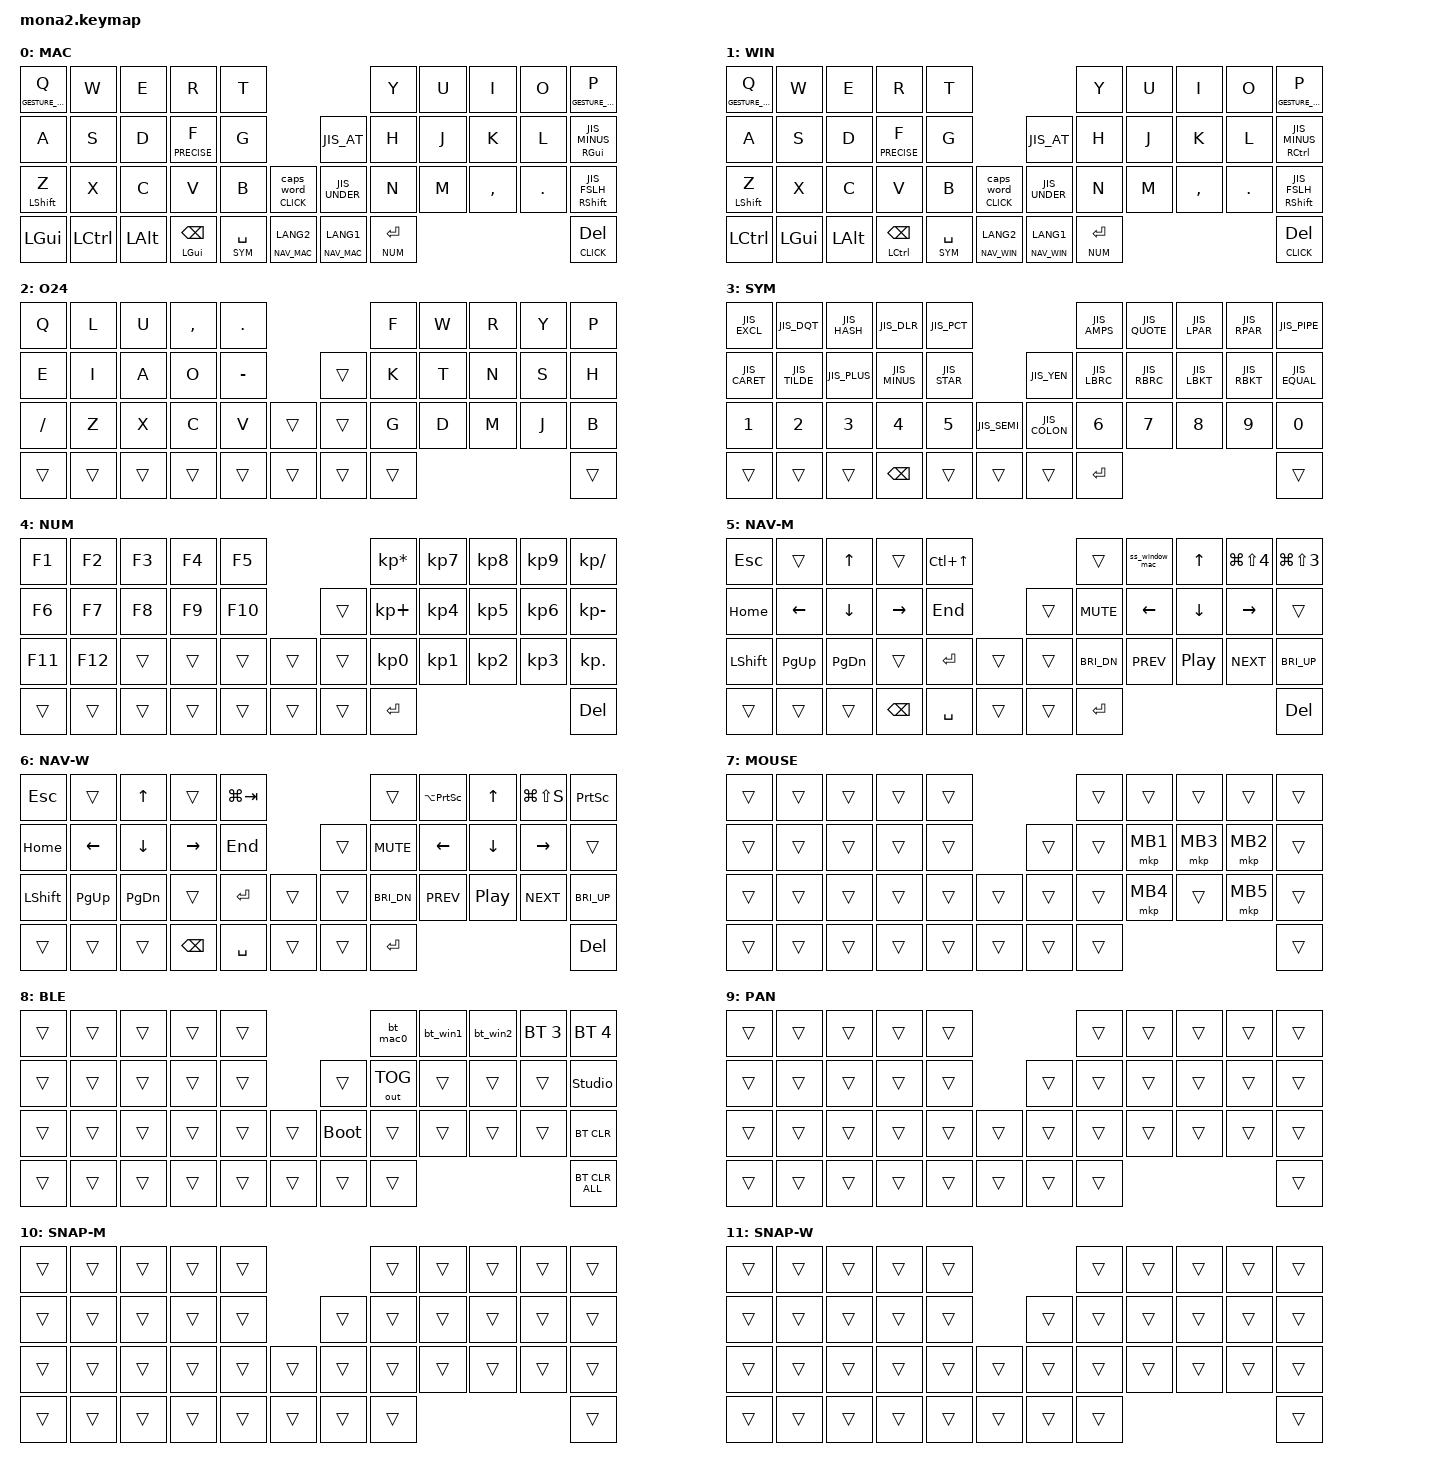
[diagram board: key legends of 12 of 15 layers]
/*
 * moNa2 keymap - JIS運用 / WIN・MAC分離 / DYA Studio対応
 * 設計: docs/keymap-phase1.md
 * レイアウト図: keymap-drawer/mona2_jis.svg
 */

#include <input/processors.dtsi>
#include <input/processors/runtime-input-processor.dtsi>
#include <behaviors/runtime-sensor-rotate.dtsi>
// DYA Studio で作ったマクロを &rmacro <slot> でキーに割り当てられるようにする
#include <behaviors/runtime_macro.dtsi>
#include <dt-bindings/zmk/input_transform.h>
#include <zephyr/dt-bindings/input/input-event-codes.h>
#include "jis.h"
#include <dt-bindings/zmk/mouse-gesture.h>
#include <behaviors.dtsi>
#include <dt-bindings/zmk/bt.h>
#include <dt-bindings/zmk/keys.h>
#include <dt-bindings/zmk/outputs.h>
#include <dt-bindings/zmk/pointing.h>

/* エンコーダ1クリックのスクロール量 ≈ SCRL_VAL × MSC_TICK_MS × (tap-ms 中の tick 数) / 1000。
 * &msc は MSC_TICK_MS ごとにスクロールを出す。tap-ms=20 だと tick は 8/16ms の2回なので
 * 130 × 0.008 × 2 ≈ 2 段。旧設定 (30, 16ms, tap-ms=100) も 0.48 × 6 tick ≈ 2 段で量は同じ。
 * 1クリックでビヘイビアキューが tap-ms だけ止まるので、tap-ms=20 なら毎秒約50クリック
 * (5回転) まで遅れずに追従する。旧 100ms では毎秒10クリックで、一気に回すと追いつきが長かった */
#define ZMK_POINTING_DEFAULT_SCRL_VAL 130
#define MSC_TICK_MS 8

/* mod-tap 誤爆対策 (&mt / mt_bspc):
 * 直前のキー入力からこの時間(ms)以内は hold(修飾キー)が発動せず tap 扱いになる。
 * 0 にすると無効化(従来挙動) */
#define MT_REQUIRE_PRIOR_IDLE_MS 125

/* ---- レイヤー定義 ---- */

#define MAC          0   // ベース(Mac)        — デフォルト
#define WIN          1   // ベース(Windows)
#define O24          2   // 代替アルファ（Q+Pトグル）
#define SYM          3   // 記号
#define NUM          4   // 数字(右手テンキー)
#define NAV_MAC      5   // 矢印/ナビ(Mac)     — P=Cmd+Shift+3
#define NAV_WIN      6   // 矢印/ナビ(Windows) — P=PrtSc
#define MOUSE        7   // マウス(オートマウスレイヤー)
#define BLE          8   // BT/設定
#define GESTURE_PAN  9   // P長押し → 2D自由スクロール(パン)
#define GESTURE_SNAP_MAC 10  // Q長押し(Mac) → ウィンドウスナップ(Rectangle)
#define GESTURE_SNAP_WIN 11  // Q長押し(Win) → ウィンドウスナップ(Win+矢印)
#define CURSOR       12  // (現在未使用)  長押し → トラックボールで矢印キー入力
#define CLICK        13  // 長押し → クリック層（カーソル移動はそのまま、指でクリック）
#define PRECISE      14  // F 長押し(400ms) → 精密モード（カーソル減速 + 右手クリック）

/* エンコーダ用 &msc の出力間隔 (既定 16ms)。短くして1クリック目からすぐスクロールさせる */
&msc {
    trigger-period-ms = <MSC_TICK_MS>;
};

&mt {
    flavor = "balanced";
    quick-tap-ms = <0>;
#if MT_REQUIRE_PRIOR_IDLE_MS > 0
    require-prior-idle-ms = <MT_REQUIRE_PRIOR_IDLE_MS>;
#endif
};

&lt {
    quick-tap-ms = <200>;
    flavor = "balanced";
};

/ {
    /* ---- コンボ (DYA Studio から編集可能) ----
     *
     * 旧 `combos { compatible = "zmk,combos"; }` はコンパイル時固定で DYA Studio
     * から編集できないため、zmk-feature-runtime-combo の「コンパイル時デフォルト」
     * ノードへ移行した。ここに書いた内容はフラッシュ直後から有効で、
     * settings_reset をかけても復活する。
     *
     * 【重要】DYA Studio 側で編集するとそのスロットだけフラッシュ上で上書きされ、
     * 以後 .keymap を書き換えても反映されない。ファーム側の値へ戻すには
     * Web UI の "Reset to Default" か settings_reset.uf2 が必要。
     *
     * スロット総数は CONFIG_ZMK_RUNTIME_COMBO_MAX_COMBOS (=16)。
     * 未使用スロット 8〜15 は DYA Studio から自由に追加できる。
     * timeout の既定は CONFIG_ZMK_RUNTIME_COMBO_DEFAULT_TIMEOUT_MS (=50、旧 zmk,combos と同値)。
     */
    runtime_combo_defaults {
        compatible = "cormoran,runtime-combo-defaults";

        // S+D = Tab
        combo_tab {
            slot = <0>;
            display-name = "Tab";
            bindings = <&kp TAB>;
            key-positions = <11 12>;
            layers = <WIN MAC>;
        };

        // D+F = Shift+Tab
        combo_stab {
            slot = <1>;
            display-name = "Shift+Tab";
            bindings = <&kp LS(TAB)>;
            key-positions = <12 13>;
            layers = <WIN MAC>;
        };

        // 英数+かな = tap:Esc / hold:BLE層 (sayu-hub意識)
        // NOTE: BLE 層は studio_unlock の唯一の入口。Studio でこのスロットを
        //       壊すと Studio に入れなくなるが、settings_reset.uf2 で復旧できる。
        combo_esc_ble {
            slot = <2>;
            display-name = "Esc / BLE";
            bindings = <&lt BLE ESC>;
            key-positions = <38 39>;
            layers = <WIN MAC O24>;  // O24 トグル中も BLE 層へ入れるよう含める
        };

        // J+K = コピー / K+L = ペースト (OS別に修飾を分岐)
        combo_copy_mac {
            slot = <3>;
            display-name = "Copy (Mac)";
            bindings = <&kp LG(C)>;
            key-positions = <17 18>;
            layers = <MAC>;
        };

        combo_copy_win {
            slot = <4>;
            display-name = "Copy (Win)";
            bindings = <&kp LC(C)>;
            key-positions = <17 18>;
            layers = <WIN>;
        };

        combo_paste_mac {
            slot = <5>;
            display-name = "Paste (Mac)";
            bindings = <&kp LG(V)>;
            key-positions = <18 19>;
            layers = <MAC>;
        };

        combo_paste_win {
            slot = <6>;
            display-name = "Paste (Win)";
            bindings = <&kp LC(V)>;
            key-positions = <18 19>;
            layers = <WIN>;
        };

        combo_toO24 {
            slot = <7>;
            display-name = "O24 toggle";
            bindings = <&tog O24>;
            key-positions = <0 9>;
            layers = <MAC WIN O24>;  // 機能層での Q+P 誤爆を防止
        };
    };

    macros {
        // OSをBTプロファイルに紐づけて切替 (BT0=Mac / BT1=Win / BT2=Win)

        bt_mac0: bt_mac0 {
            compatible = "zmk,behavior-macro";
            #binding-cells = <0>;
            bindings = <&to MAC &bt BT_SEL 0>;
            label = "BT_MAC0";
        };

        bt_win1: bt_win1 {
            compatible = "zmk,behavior-macro";
            #binding-cells = <0>;
            bindings = <&to WIN &bt BT_SEL 1>;
            label = "BT_WIN1";
        };

        bt_win2: bt_win2 {
            compatible = "zmk,behavior-macro";
            #binding-cells = <0>;
            bindings = <&to WIN &bt BT_SEL 2>;
            label = "BT_WIN2";
        };

        // Mac: ⌘⇧4 → Space で「ウィンドウ単位」スクショ (2段操作をマクロ化)

        ss_window_mac: ss_window_mac {
            compatible = "zmk,behavior-macro";
            #binding-cells = <0>;
            wait-ms = <50>;
            tap-ms = <30>;
            bindings = <&kp LG(LS(N4)) &kp SPACE>;
            label = "SS_WINDOW_MAC";
        };

        // Win: 対角スナップ (2ストローク: Win+方向 × 2)

        snap_w_tl: snap_w_tl {
            compatible = "zmk,behavior-macro";
            #binding-cells = <0>;
            wait-ms = <50>;
            tap-ms = <30>;
            bindings = <&kp LG(LEFT) &kp LG(UP)>;
            label = "SNAP_W_TL";
        };

        snap_w_tr: snap_w_tr {
            compatible = "zmk,behavior-macro";
            #binding-cells = <0>;
            wait-ms = <50>;
            tap-ms = <30>;
            bindings = <&kp LG(RIGHT) &kp LG(UP)>;
            label = "SNAP_W_TR";
        };

        snap_w_bl: snap_w_bl {
            compatible = "zmk,behavior-macro";
            #binding-cells = <0>;
            wait-ms = <50>;
            tap-ms = <30>;
            bindings = <&kp LG(LEFT) &kp LG(DOWN)>;
            label = "SNAP_W_BL";
        };

        snap_w_br: snap_w_br {
            compatible = "zmk,behavior-macro";
            #binding-cells = <0>;
            wait-ms = <50>;
            tap-ms = <30>;
            bindings = <&kp LG(RIGHT) &kp LG(DOWN)>;
            label = "SNAP_W_BR";
        };
    };

    behaviors {
        // Backspace 専用 mod-tap: タップ→即長押し(quick-tap)で BS をオートリピート

        mt_bspc: mt_bspc {
            compatible = "zmk,behavior-hold-tap";
            #binding-cells = <2>;
            bindings = <&kp>, <&kp>;

            flavor = "balanced";
            tapping-term-ms = <200>;
            quick-tap-ms = <200>;
#if MT_REQUIRE_PRIOR_IDLE_MS > 0
            require-prior-idle-ms = <MT_REQUIRE_PRIOR_IDLE_MS>;
#endif
        };

        // エンコーダ: runtime-sensor-rotate (DYA Studioから動的変更可)

        scroll_up_down: scroll_up_down {
            compatible = "zmk,behavior-runtime-sensor-rotate";
            #sensor-binding-cells = <0>;
            cw-binding = <&msc SCRL_DOWN>;
            ccw-binding = <&msc SCRL_UP>;
            // 1クリックでキューが tap-ms だけ止まる。100ms だと毎秒10クリックしか
            // 捌けず追いつきが長いので 20ms に (量は SCRL_VAL / MSC_TICK_MS 側で合わせてある)
            tap-ms = <20>;
        };

        rsr_vol: rsr_vol {
            compatible = "zmk,behavior-runtime-sensor-rotate";
            #sensor-binding-cells = <0>;
            cw-binding = <&kp C_VOL_DN>;
            ccw-binding = <&kp C_VOL_UP>;
            // 音量キーは押下時間で量が変わらないので、追いつきが速くなるよう短くする
            tap-ms = <20>;
        };

        // クリック層用 hold-tap: タップ=caps_word / 長押し=クリック層(CLICK)
        // caps_word は #binding-cells=0 のため、起動時はタップ側パラメータ(0)を渡すが caps_word は無視する
        clk_caps: clk_caps {
            compatible = "zmk,behavior-hold-tap";
            #binding-cells = <2>;
            flavor = "balanced";
            tapping-term-ms = <200>;
            quick-tap-ms = <200>;
            bindings = <&mo>, <&caps_word>;
        };

        // 精密モード用 hold-tap: タップ=通常の文字 / 長押し(400ms)=精密層(PRECISE)
        //
        // flavor が "tap-preferred" なのが肝。&lt や &mt が使う "balanced" は
        // 「他のキーが押されて離された」時点で hold 判定するため、F をこの方式に
        // すると `fa` `fo` と打っただけで層に落ちる。tap-preferred は
        // 「tapping-term の経過」でしか hold にならないので、
        //   - 通常のタイピングでは原理的に発動しない
        //   - D+F コンボ (timeout 50ms) が先に成立して抜ける
        // という二重の保護になる。「長押しで入る」という要求と手段が一致している。
        //
        // 代償: hold 判定が確定するまで後続キーが遅延する (`fo` の o が少し待たされる)。
        // 実害が出たら hold-trigger-key-positions で右手キー限定にする手がある。
        prec_ht: prec_ht {
            compatible = "zmk,behavior-hold-tap";
            #binding-cells = <2>;
            flavor = "tap-preferred";
            tapping-term-ms = <400>;   // 精密モードに入るまでの長押し時間。250〜500 で調整
            quick-tap-ms = <200>;      // タップ直後の押しっぱなしは文字のオートリピート
#if MT_REQUIRE_PRIOR_IDLE_MS > 0
            require-prior-idle-ms = <MT_REQUIRE_PRIOR_IDLE_MS>;  // 打鍵直後は発動しない
#endif
            bindings = <&mo>, <&kp>;
        };

    };

    keymap {
        compatible = "zmk,keymap";

        mac_layer {
            display-name = "MAC";
            bindings = <
&lt GESTURE_SNAP_MAC Q  &kp W      &kp E     &kp R               &kp T                                                  &kp Y          &kp U  &kp I      &kp O    &lt GESTURE_PAN P
&kp A                   &kp S      &kp D     &prec_ht PRECISE F  &kp G                       &kp JIS_AT             &kp H          &kp J  &kp K      &kp L    &mt RGUI JIS_MINUS
&mt LSHFT Z             &kp X      &kp C     &kp V               &kp B        &clk_caps CLICK 0     &kp JIS_UNDER          &kp N          &kp M  &kp COMMA  &kp DOT  &mt RSHFT JIS_FSLH
&kp LGUI                &kp LCTRL  &kp LALT  &mt_bspc LGUI BSPC  &lt SYM SPACE  &lt NAV_MAC LANG2    &lt NAV_MAC LANG1  &lt NUM ENTER                             &lt CLICK DEL
            >;

            sensor-bindings = <&scroll_up_down>;
        };

        win_layer {
            display-name = "WIN";
            bindings = <
&lt GESTURE_SNAP_WIN Q  &kp W     &kp E     &kp R                &kp T                                                  &kp Y          &kp U  &kp I      &kp O    &lt GESTURE_PAN P
&kp A                  &kp S     &kp D     &prec_ht PRECISE F   &kp G                       &kp JIS_AT             &kp H          &kp J  &kp K      &kp L    &mt RCTRL JIS_MINUS
&mt LSHFT Z            &kp X     &kp C     &kp V                &kp B        &clk_caps CLICK 0     &kp JIS_UNDER          &kp N          &kp M  &kp COMMA  &kp DOT  &mt RSHFT JIS_FSLH
&kp LCTRL              &kp LGUI  &kp LALT  &mt_bspc LCTRL BSPC  &lt SYM SPACE  &lt NAV_WIN LANG2    &lt NAV_WIN LANG1  &lt NUM ENTER                             &lt CLICK DEL
            >;

            sensor-bindings = <&scroll_up_down>;
        };

        O24 {
            display-name = "O24";
            bindings = <
&kp Q     &kp L   &kp U   &kp COMMA  &kp DOT                      &kp F   &kp W  &kp R  &kp Y  &kp P
&kp E     &kp I   &kp A   &kp O      &kp MINUS            &trans  &kp K   &kp T  &kp N  &kp S  &kp H
&kp FSLH  &kp Z   &kp X   &kp C      &kp V      &trans    &trans  &kp G   &kp D  &kp M  &kp J  &kp B
&trans    &trans  &trans  &trans     &trans     &trans    &trans  &trans                       &trans
            >;

            sensor-bindings = <&scroll_up_down>;
        };

        sym_layer {
            display-name = "SYM";
            bindings = <
&kp JIS_EXCL   &kp JIS_DQT    &kp JIS_HASH  &kp JIS_DLR    &kp JIS_PCT                                  &kp JIS_AMPS  &kp JIS_QUOTE  &kp JIS_LPAR  &kp JIS_RPAR  &kp JIS_PIPE
&kp JIS_CARET  &kp JIS_TILDE  &kp JIS_PLUS  &kp JIS_MINUS  &kp JIS_STAR                  &kp JIS_YEN    &kp JIS_LBRC  &kp JIS_RBRC   &kp JIS_LBKT  &kp JIS_RBKT  &kp JIS_EQUAL
&kp N1         &kp N2         &kp N3        &kp N4         &kp N5        &kp JIS_SEMI    &kp JIS_COLON  &kp N6        &kp N7         &kp N8        &kp N9        &kp N0
&trans         &trans         &trans        &kp BSPC       &trans        &trans          &trans         &kp ENTER                                                &trans
            >;

            sensor-bindings = <&scroll_up_down>;
        };

        num_layer {
            display-name = "NUM";
            bindings = <
&kp F1   &kp F2   &kp F3  &kp F4  &kp F5                     &kp KP_MULTIPLY  &kp KP_N7  &kp KP_N8  &kp KP_N9  &kp KP_DIVIDE
&kp F6   &kp F7   &kp F8  &kp F9  &kp F10            &trans  &kp KP_PLUS      &kp KP_N4  &kp KP_N5  &kp KP_N6  &kp KP_MINUS
&kp F11  &kp F12  &trans  &trans  &trans   &trans    &trans  &kp KP_N0        &kp KP_N1  &kp KP_N2  &kp KP_N3  &kp KP_DOT
&trans   &trans   &trans  &trans  &trans   &trans    &trans  &kp ENTER                                         &kp DEL
            >;

            sensor-bindings = <&scroll_up_down>;
        };

        nav_mac_layer {
            display-name = "NAV-M";
            bindings = <
&kp ESC    &trans     &kp UP     &trans     &kp LC(UP)                    &trans        &ss_window_mac  &kp UP    &kp LG(LS(N4))  &kp LG(LS(N3))
&kp HOME   &kp LEFT   &kp DOWN   &kp RIGHT  &kp END               &trans  &kp C_MUTE    &kp LEFT        &kp DOWN  &kp RIGHT       &trans
&kp LSHFT  &kp PG_UP  &kp PG_DN  &trans     &kp ENTER   &trans    &trans  &kp C_BRI_DN  &kp C_PREV      &kp C_PP  &kp C_NEXT      &kp C_BRI_UP
&trans     &trans     &trans     &kp BSPC   &kp SPACE   &trans    &trans  &kp ENTER                                               &kp DEL
            >;

            sensor-bindings = <&rsr_vol>;
        };

        nav_win_layer {
            display-name = "NAV-W";
            bindings = <
&kp ESC    &trans     &kp UP     &trans     &kp LG(TAB)                    &trans        &kp LA(PSCRN)  &kp UP    &kp LG(LS(S))  &kp PSCRN
&kp HOME   &kp LEFT   &kp DOWN   &kp RIGHT  &kp END                &trans  &kp C_MUTE    &kp LEFT       &kp DOWN  &kp RIGHT      &trans
&kp LSHFT  &kp PG_UP  &kp PG_DN  &trans     &kp ENTER    &trans    &trans  &kp C_BRI_DN  &kp C_PREV     &kp C_PP  &kp C_NEXT     &kp C_BRI_UP
&trans     &trans     &trans     &kp BSPC   &kp SPACE    &trans    &trans  &kp ENTER                                             &kp DEL
            >;

            sensor-bindings = <&rsr_vol>;
        };

        mouse_layer {
            display-name = "MOUSE";
            bindings = <
&trans  &trans  &trans  &trans  &trans                    &trans  &trans    &trans    &trans    &trans
&trans  &trans  &trans  &trans  &trans            &trans  &trans  &mkp MB1  &mkp MB3  &mkp MB2  &trans
&trans  &trans  &trans  &trans  &trans  &trans    &trans  &trans  &mkp MB4  &trans    &mkp MB5  &trans
&trans  &trans  &trans  &trans  &trans  &trans    &trans  &trans                                &trans
            >;

            sensor-bindings = <&scroll_up_down>;
        };

        ble_layer {
            display-name = "BLE";
            bindings = <
&trans  &trans  &trans  &trans  &trans                         &bt_mac0      &bt_win1  &bt_win2  &bt BT_SEL 3  &bt BT_SEL 4
&trans  &trans  &trans  &trans  &trans            &trans       &out OUT_TOG  &trans    &trans    &trans        &studio_unlock
&trans  &trans  &trans  &trans  &trans  &trans    &bootloader  &trans        &trans    &trans    &trans        &bt BT_CLR
&trans  &trans  &trans  &trans  &trans  &trans    &trans       &trans                                          &bt BT_CLR_ALL
            >;

            sensor-bindings = <&rsr_vol>;
        };

        gesture_pan_layer {
            display-name = "PAN";
            bindings = <
&trans  &trans  &trans  &trans  &trans                    &trans  &trans  &trans  &trans  &trans
&trans  &trans  &trans  &trans  &trans            &trans  &trans  &trans  &trans  &trans  &trans
&trans  &trans  &trans  &trans  &trans  &trans    &trans  &trans  &trans  &trans  &trans  &trans
&trans  &trans  &trans  &trans  &trans  &trans    &trans  &trans                          &trans
            >;

            sensor-bindings = <&scroll_up_down>;
        };

        gesture_snap_mac_layer {
            display-name = "SNAP-M";
            bindings = <
&trans  &trans  &trans  &trans  &trans                    &trans  &trans  &trans  &trans  &trans
&trans  &trans  &trans  &trans  &trans            &trans  &trans  &trans  &trans  &trans  &trans
&trans  &trans  &trans  &trans  &trans  &trans    &trans  &trans  &trans  &trans  &trans  &trans
&trans  &trans  &trans  &trans  &trans  &trans    &trans  &trans                          &trans
            >;

            sensor-bindings = <&scroll_up_down>;
        };

        gesture_snap_win_layer {
            display-name = "SNAP-W";
            bindings = <
&trans  &trans  &trans  &trans  &trans                    &trans  &trans  &trans  &trans  &trans
&trans  &trans  &trans  &trans  &trans            &trans  &trans  &trans  &trans  &trans  &trans
&trans  &trans  &trans  &trans  &trans  &trans    &trans  &trans  &trans  &trans  &trans  &trans
&trans  &trans  &trans  &trans  &trans  &trans    &trans  &trans                          &trans
            >;

            sensor-bindings = <&scroll_up_down>;
        };

        cursor_layer {
            display-name = "CURSOR";
            bindings = <
&trans  &trans  &trans  &trans  &trans                    &trans  &trans  &trans  &trans  &trans
&trans  &trans  &trans  &trans  &trans            &trans  &trans  &trans  &trans  &trans  &trans
&trans  &trans  &trans  &trans  &trans  &trans    &trans  &trans  &trans  &trans  &trans  &trans
&trans  &trans  &trans  &trans  &trans  &trans    &trans  &trans                          &trans
            >;

            sensor-bindings = <&scroll_up_down>;
        };

        // クリック層: DEL長押し or 「Bの一つ右」長押しで起動。両手にクリッククラスタ。
        // トラックボールはデフォルトチェーンを通るのでカーソルは普通に動き、AMLと独立して共存する。
        // 左手 S/D/F=左/中/右クリック・X/V=戻る/進む / 右手 J/K/L=左/中/右クリック・M/.=戻る/進む
        click_layer {
            display-name = "CLICK";
            bindings = <
&trans  &trans    &trans    &trans    &trans                              &trans  &trans    &trans    &trans    &trans
&trans  &mkp MB1  &mkp MB3  &mkp MB2  &trans            &trans            &trans  &mkp MB1  &mkp MB3  &mkp MB2  &trans
&trans  &mkp MB4  &trans    &mkp MB5  &trans  &trans    &trans            &trans  &mkp MB4  &trans    &mkp MB5  &trans
&trans  &trans    &trans    &trans    &trans  &trans    &trans  &trans                                          &trans
            >;

            sensor-bindings = <&scroll_up_down>;
        };

        // 精密層: F 長押し(400ms)で起動。右手クリック + カーソル減速。
        // カーソル減速は boards/shields/mona2/mona2_r.overlay の
        // trackball_central_listener/precision (layers = <14>) が担当する。
        // CLICK 層と違い左手はクリックを持たない (起動キーの F を左手が押さえているため)。
        // 右手 J/K/L=左/中/右クリック・M/.=戻る/進む (CLICK 層の右手と同一配置)
        precise_layer {
            display-name = "PRECISE";
            bindings = <
&trans  &trans  &trans  &trans  &trans                              &trans  &trans    &trans    &trans    &trans
&trans  &trans  &trans  &trans  &trans            &trans            &trans  &mkp MB1  &mkp MB3  &mkp MB2  &trans
&trans  &trans  &trans  &trans  &trans  &trans    &trans            &trans  &mkp MB4  &trans    &mkp MB5  &trans
&trans  &trans  &trans  &trans  &trans  &trans    &trans  &trans                                          &trans
            >;

            sensor-bindings = <&scroll_up_down>;
        };
    };
};

// ---- マウスジェスチャー設定 ----
// Mac: Rectangle のデフォルトショートカット (Ctrl+Option+矢印)。変更する場合はここを修正。

&zip_mouse_gesture {
    stroke-size = <200>;          // cpi=800 でフリック距離が従来(150@600cpi)と同等になる値
    enable-eager-mode;
    gesture-cooldown-ms = <200>;
    always-active;                // &lt によるレイヤー起動のみで動作させる(起動キー &mouse_gesture 不要)

    snap_left {
        pattern = <GESTURE_LEFT>;
        bindings = <&kp LC(LA(LEFT))>;
    };

    snap_right {
        pattern = <GESTURE_RIGHT>;
        bindings = <&kp LC(LA(RIGHT))>;
    };

    snap_max {
        pattern = <GESTURE_UP>;
        bindings = <&kp LC(LA(RET))>;
    };

    snap_center {
        pattern = <GESTURE_DOWN>;
        bindings = <&kp LC(LA(C))>;
    };

    // 四隅(↖↗↙↘): モジュールが4方向のみ認識するため現状発火しない（将来対応時に備えて残置）
    snap_tl {
        pattern = <GESTURE_UP_LEFT>;
        bindings = <&kp LC(LA(U))>;
    };

    snap_tr {
        pattern = <GESTURE_UP_RIGHT>;
        bindings = <&kp LC(LA(I))>;
    };

    snap_bl {
        pattern = <GESTURE_DOWN_LEFT>;
        bindings = <&kp LC(LA(J))>;
    };

    snap_br {
        pattern = <GESTURE_DOWN_RIGHT>;
        bindings = <&kp LC(LA(K))>;
    };
};

// Win: 標準スナップ (Win+矢印)

&zip_mouse_gesture_win {
    stroke-size = <200>;          // cpi=800 でフリック距離が従来(150@600cpi)と同等になる値
    enable-eager-mode;
    gesture-cooldown-ms = <200>;
    always-active;                // &lt によるレイヤー起動のみで動作させる(起動キー &mouse_gesture 不要)

    snap_left_w {
        pattern = <GESTURE_LEFT>;
        bindings = <&kp LG(LEFT)>;
    };

    snap_right_w {
        pattern = <GESTURE_RIGHT>;
        bindings = <&kp LG(RIGHT)>;
    };

    snap_max_w {
        pattern = <GESTURE_UP>;
        bindings = <&kp LG(UP)>;
    };

    snap_rest_w {
        pattern = <GESTURE_DOWN>;
        bindings = <&kp LG(DOWN)>;
    };

    // 四隅(↖↗↙↘): モジュールが4方向のみ認識するため現状発火しない（将来対応時に備えて残置）
    snap_tl_w {
        pattern = <GESTURE_UP_LEFT>;
        bindings = <&snap_w_tl>;
    };

    snap_tr_w {
        pattern = <GESTURE_UP_RIGHT>;
        bindings = <&snap_w_tr>;
    };

    snap_bl_w {
        pattern = <GESTURE_DOWN_LEFT>;
        bindings = <&snap_w_bl>;
    };

    snap_br_w {
        pattern = <GESTURE_DOWN_RIGHT>;
        bindings = <&snap_w_br>;
    };
};
